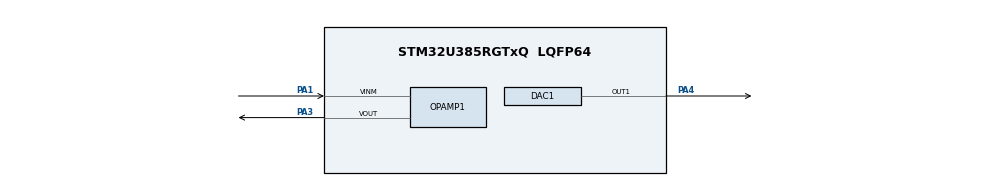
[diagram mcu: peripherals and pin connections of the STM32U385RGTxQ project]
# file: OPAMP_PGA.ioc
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CORTEX_M33_NS.userName=CORTEX_M33
DAC1.DAC_AutonomousMode=DAC_AUTONOMOUS_MODE_DISABLE
DAC1.DAC_Channel-DAC_OUT1_ExtAndInt=DAC_CHANNEL_1
DAC1.DAC_Channel-DAC_OUT2_ExtAndInt=DAC_CHANNEL_1
DAC1.DAC_Trigger-DAC_OUT1_ExtAndInt=DAC_TRIGGER_T2_TRGO
DAC1.DAC_Trigger-DAC_OUT2_ExtAndInt=DAC_TRIGGER_T2_TRGO
GPDMA1.CIRCULARMODE_GPDMACH1=ENABLE
GPDMA1.DESTDATAWIDTH_GPDMACH1=DMA_DEST_DATAWIDTH_WORD
GPDMA1.DIRECTION_GPDMACH1=DMA_MEMORY_TO_PERIPH
GPDMA1.IPHANDLE_GPDMACH1-SIMPLEREQUEST_GPDMACH1=__NULL
GPDMA1.LINKALLOCATEDPORT_CIRCULAR_GPDMACH1=DMA_LINK_ALLOCATED_PORT0
GPDMA1.REQUEST_GPDMACH1=GPDMA1_REQUEST_DAC1_CH1
GPDMA1.SRCDATAWIDTH_GPDMACH1=DMA_SRC_DATAWIDTH_HALFWORD
GPDMA1.SRCINC_GPDMACH1=DMA_SINC_INCREMENTED
GPDMA1.TRANSFERALLOCATEDPORTSRC_GPDMACH1=DMA_SRC_ALLOCATED_PORT1
Mcu.Family=STM32U3
Mcu.Name=STM32U385RGTxQ
Mcu.Package=LQFP64
NVIC.GPDMA1_Channel1_IRQn=true\:0\:0\:false\:false\:true\:false\:true\:true
NVIC.PriorityGroup=NVIC_PRIORITYGROUP_4
PA1.Mode=PGA Connected-DAC_OUT1-INP
PA1.PinAttribute=CortexM33
PA1.Signal=OPAMP1_VINM
PA3.Mode=PGA Connected-DAC_OUT1-INP
PA3.PinAttribute=CortexM33
PA3.Signal=OPAMP1_VOUT
PA4.PinAttribute=CortexM33
PA4.Signal=COMP_DAC11_group
ProjectManager.HeapSize=0x200
ProjectManager.StackSize=0x400
ProjectManager.TargetToolchain=EWARM V9.20
RCC.ADCFreq_Value=96000000
RCC.AHBFreq_Value=96000000
RCC.APB1Freq_Value=96000000
RCC.APB1TimFreq_Value=96000000
RCC.APB2Freq_Value=96000000
RCC.APB2TimFreq_Value=96000000
RCC.APB3Freq_Value=96000000
RCC.CortexFreq_Value=12000000
RCC.HCLKFreq_Value=96000000
RCC.HSE_VALUE=16000000
RCC.HSI48_VALUE=48000000
RCC.HSI_VALUE=16000000
RCC.LSE_VALUE=32768
RCC.LSIDIV_VALUE=32000
RCC.MSISDIV=RCC_MSI_DIV1
RCC.MSI_VALUE=96000000
RCC.PWR_Regulator_Voltage_Scale=PWR_REGULATOR_VOLTAGE_SCALE1
RCC.SYSCLKFreq_VALUE=96000000
RCC.USBFreq_Value=96000000
SH.COMP_DAC11_group.0=DAC1_OUT1,DAC_OUT1_ExtAndInt
TIM2.AutoReloadPreload=TIM_AUTORELOAD_PRELOAD_DISABLE
TIM2.ClockDivision=TIM_CLOCKDIVISION_DIV1
TIM2.CounterMode=TIM_COUNTERMODE_UP
TIM2.Dithering=Disable
TIM2.Period=0xFFFF
TIM2.PeriodNoDither=0xFFFF
TIM2.Prescaler=0
TIM2.TIM_MasterOutputTrigger=TIM_TRGO_UPDATE
TIM2.TIM_MasterSlaveMode=TIM_MASTERSLAVEMODE_DISABLE
VP_GPDMA1_VS_GPDMACH1.Mode=SIMPLEREQUEST_GPDMACH1
VP_ICACHE_VS_ICACHE.Mode=DirectMappedCache
VP_PWR_VS_DBSignals.Mode=DisableDeadBatterySignals
VP_PWR_VS_LPOM.Mode=PowerOptimisation
VP_PWR_VS_SECSignals.Mode=Security/Privilege
VP_TIM2_VS_ClockSourceINT.Mode=Internal
board=custom

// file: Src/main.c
/* USER CODE BEGIN Header */
/**
  ******************************************************************************
  * @file           : main.c
  * @brief          : Main program body
  ******************************************************************************
  * @attention
  *
  * Copyright (c) 2024 STMicroelectronics.
  * All rights reserved.
  *
  * This software is licensed under terms that can be found in the LICENSE file
  * in the root directory of this software component.
  * If no LICENSE file comes with this software, it is provided AS-IS.
  *
  ******************************************************************************
  */
/* USER CODE END Header */
#include "main.h"

/* USER CODE BEGIN Includes */
#include "stm32u3xx_nucleo.h"
/* USER CODE END Includes */

DAC_HandleTypeDef hdac1;
DMA_NodeTypeDef Node_GPDMA1_Channel1;
DMA_QListTypeDef List_GPDMA1_Channel1;
DMA_HandleTypeDef handle_GPDMA1_Channel1;

OPAMP_HandleTypeDef hopamp1;

TIM_HandleTypeDef htim2;

/* USER CODE BEGIN PV */
/* Private variables ---------------------------------------------------------*/
/* set to 1 after User push-button interrupt  */
__IO uint32_t UserButtonStatus = 0;

const uint16_t Sine12bit[32] = { 511,  611,  707,  796,  873,  937,  984, 1013,
                                1023, 1013,  984,  937,  873,  796,  707,  611,
                                 511,  412,  315,  227,  149,   86,   38,    9,
                                   0,    9,   38,   86,  149,  227,  315,  412};
/* USER CODE END PV */

void SystemClock_Config(void);
static void MX_GPIO_Init(void);
static void MX_GPDMA1_Init(void);
static void MX_DAC1_Init(void);
static void MX_ICACHE_Init(void);
static void MX_TIM2_Init(void);
static void MX_OPAMP1_Init(void);
/* USER CODE BEGIN PFP */
/* Private function prototypes -----------------------------------------------*/
void OPAMP_Config_lowPower(void);
void DAC_Config_lowPower(void);
/* USER CODE END PFP */

int main(void)
{

  /* MCU Configuration--------------------------------------------------------*/

  /* Reset of all peripherals, Initializes the Flash interface and the Systick. */
  HAL_Init();

  /* Configure the system clock */
  SystemClock_Config();

  /* Initialize all configured peripherals */
  MX_GPIO_Init();
  MX_GPDMA1_Init();
  MX_DAC1_Init();
  MX_ICACHE_Init();
  MX_TIM2_Init();
  MX_OPAMP1_Init();
  /* USER CODE BEGIN 2 */
  /* Initialize the User push-button.
     It is used for changing the gain */
  BSP_PB_Init(BUTTON_USER, BUTTON_MODE_EXTI);
  /* USER CODE END 2 */

  /* Infinite loop */
  /* USER CODE BEGIN WHILE */
  /*##- Enable DAC Channel and associated DMA ##############################*/
  if(HAL_OK != HAL_DAC_Start_DMA(&hdac1, DAC_CHANNEL_1,
                       (uint32_t*)Sine12bit, 32, DAC_ALIGN_12B_R))
  {
    /* Start DMA Error */
    Error_Handler();
  }
  /*##- Enable TIM peripheral counter ######################################*/
  if(HAL_OK != HAL_TIM_Base_Start(&htim2))
  {
    Error_Handler();
  }
  /*##- Start OPAMP    #####################################################*/
  /* Enable OPAMP */
  if(HAL_OK != HAL_OPAMP_Start(&hopamp1))
  {
    Error_Handler();
  }

  while (1)
  {
    /* Test if user an action occurred on the User push-button */
    if (UserButtonStatus == 1)
    {
      HAL_Delay(200);
      UserButtonStatus = 0;
      /* Change the gain */
      if (hopamp1.Init.PgaGain == OPAMP_PGA_GAIN_4)
      {
        hopamp1.Init.PgaGain = OPAMP_PGA_GAIN_2;
      }
      else
      {
        hopamp1.Init.PgaGain = OPAMP_PGA_GAIN_4;
      }
      /* Update OPAMP config */
      /* Gain is changed on the fly */
      if(HAL_OK != HAL_OPAMP_Init(&hopamp1))
      {
        Error_Handler();
      }
    }
  }
    /* USER CODE END WHILE */

}

void SystemClock_Config(void)
{
  RCC_OscInitTypeDef RCC_OscInitStruct = {0};
  RCC_ClkInitTypeDef RCC_ClkInitStruct = {0};

  /** Enable Epod Booster
  */
  if (HAL_RCCEx_EpodBoosterClkConfig(RCC_EPODBOOSTER_SOURCE_MSIS, RCC_EPODBOOSTER_DIV1) != HAL_OK)
  {
    Error_Handler();
  }
  if (HAL_PWREx_EnableEpodBooster() != HAL_OK)
  {
    Error_Handler();
  }

  /** Configure the main internal regulator output voltage
  */
  if (HAL_PWREx_ControlVoltageScaling(PWR_REGULATOR_VOLTAGE_SCALE1) != HAL_OK)
  {
    Error_Handler();
  }

  /** Set Flash latency before increasing MSIS
  */
  __HAL_FLASH_SET_LATENCY(FLASH_LATENCY_2);

  /** Initializes the CPU, AHB and APB buses clocks
  */
  RCC_OscInitStruct.OscillatorType = RCC_OSCILLATORTYPE_LSI|RCC_OSCILLATORTYPE_MSIS;
  RCC_OscInitStruct.LSIState = RCC_LSI_ON;
  RCC_OscInitStruct.LSIDiv = RCC_LSI_DIV1;
  RCC_OscInitStruct.MSISState = RCC_MSI_ON;
  RCC_OscInitStruct.MSISSource = RCC_MSI_RC0;
  RCC_OscInitStruct.MSISDiv = RCC_MSI_DIV1;
  if (HAL_RCC_OscConfig(&RCC_OscInitStruct) != HAL_OK)
  {
    Error_Handler();
  }

  /** Initializes the CPU, AHB and APB buses clocks
  */
  RCC_ClkInitStruct.ClockType = RCC_CLOCKTYPE_HCLK|RCC_CLOCKTYPE_SYSCLK
                              |RCC_CLOCKTYPE_PCLK1|RCC_CLOCKTYPE_PCLK2
                              |RCC_CLOCKTYPE_PCLK3;
  RCC_ClkInitStruct.SYSCLKSource = RCC_SYSCLKSOURCE_MSIS;
  RCC_ClkInitStruct.AHBCLKDivider = RCC_SYSCLK_DIV1;
  RCC_ClkInitStruct.APB1CLKDivider = RCC_HCLK_DIV1;
  RCC_ClkInitStruct.APB2CLKDivider = RCC_HCLK_DIV1;
  RCC_ClkInitStruct.APB3CLKDivider = RCC_HCLK_DIV1;

  if (HAL_RCC_ClockConfig(&RCC_ClkInitStruct, FLASH_LATENCY_2) != HAL_OK)
  {
    Error_Handler();
  }
}

static void MX_DAC1_Init(void)
{

  DAC_ChannelConfTypeDef sConfig = {0};
  DAC_AutonomousModeConfTypeDef sAutonomousMode = {0};

  /** DAC Initialization
  */
  hdac1.Instance = DAC1;
  if (HAL_DAC_Init(&hdac1) != HAL_OK)
  {
    Error_Handler();
  }

  /** DAC channel OUT1 config
  */
  sConfig.DAC_HighFrequency = DAC_HIGH_FREQUENCY_INTERFACE_MODE_DISABLE;
  sConfig.DAC_DMADoubleDataMode = DISABLE;
  sConfig.DAC_SignedFormat = DISABLE;
  sConfig.DAC_SampleAndHold = DAC_SAMPLEANDHOLD_DISABLE;
  sConfig.DAC_Trigger = DAC_TRIGGER_T2_TRGO;
  sConfig.DAC_OutputBuffer = DAC_OUTPUTBUFFER_ENABLE;
  sConfig.DAC_ConnectOnChipPeripheral = DAC_CHIPCONNECT_BOTH;
  sConfig.DAC_UserTrimming = DAC_TRIMMING_FACTORY;
  if (HAL_DAC_ConfigChannel(&hdac1, &sConfig, DAC_CHANNEL_1) != HAL_OK)
  {
    Error_Handler();
  }

  /** Configure Autonomous Mode
  */
  sAutonomousMode.AutonomousModeState = DAC_AUTONOMOUS_MODE_DISABLE;
  if (HAL_DACEx_SetConfigAutonomousMode(&hdac1, &sAutonomousMode) != HAL_OK)
  {
    Error_Handler();
  }

}

static void MX_GPDMA1_Init(void)
{

  /* Peripheral clock enable */
  __HAL_RCC_GPDMA1_CLK_ENABLE();

  /* GPDMA1 interrupt Init */
    HAL_NVIC_SetPriority(GPDMA1_Channel1_IRQn, 0, 0);
    HAL_NVIC_EnableIRQ(GPDMA1_Channel1_IRQn);

}

static void MX_ICACHE_Init(void)
{

  /** Enable instruction cache in 1-way (direct mapped cache)
  */
  if (HAL_ICACHE_ConfigAssociativityMode(ICACHE_1WAY) != HAL_OK)
  {
    Error_Handler();
  }
  if (HAL_ICACHE_Enable() != HAL_OK)
  {
    Error_Handler();
  }

}

static void MX_OPAMP1_Init(void)
{

  hopamp1.Instance = OPAMP1;
  hopamp1.Init.Mode = OPAMP_PGA_MODE;
  hopamp1.Init.NonInvertingInput = OPAMP_NONINVERTINGINPUT_DAC_CH;
  hopamp1.Init.InvertingInput = OPAMP_INVERTINGINPUT_IO0;
  hopamp1.Init.PowerMode = OPAMP_POWERMODE_NORMALPOWER_NORMALSPEED;
  hopamp1.Init.PgaGain = OPAMP_PGA_GAIN_2;
  hopamp1.Init.UserTrimming = OPAMP_TRIMMING_FACTORY;
  if (HAL_OPAMP_Init(&hopamp1) != HAL_OK)
  {
    Error_Handler();
  }

}

static void MX_TIM2_Init(void)
{

  TIM_ClockConfigTypeDef sClockSourceConfig = {0};
  TIM_MasterConfigTypeDef sMasterConfig = {0};

  htim2.Instance = TIM2;
  htim2.Init.Prescaler = 0;
  htim2.Init.CounterMode = TIM_COUNTERMODE_UP;
  htim2.Init.Period = 0xFFFF;
  htim2.Init.ClockDivision = TIM_CLOCKDIVISION_DIV1;
  htim2.Init.AutoReloadPreload = TIM_AUTORELOAD_PRELOAD_DISABLE;
  if (HAL_TIM_Base_Init(&htim2) != HAL_OK)
  {
    Error_Handler();
  }
  sClockSourceConfig.ClockSource = TIM_CLOCKSOURCE_INTERNAL;
  if (HAL_TIM_ConfigClockSource(&htim2, &sClockSourceConfig) != HAL_OK)
  {
    Error_Handler();
  }
  sMasterConfig.MasterOutputTrigger = TIM_TRGO_UPDATE;
  sMasterConfig.MasterSlaveMode = TIM_MASTERSLAVEMODE_DISABLE;
  if (HAL_TIMEx_MasterConfigSynchronization(&htim2, &sMasterConfig) != HAL_OK)
  {
    Error_Handler();
  }

}

static void MX_GPIO_Init(void)
{

  /* GPIO Ports Clock Enable */
  __HAL_RCC_GPIOA_CLK_ENABLE();

}

/* USER CODE BEGIN 4 */

/**
  * @brief  EXTI line detection callbacks.
  * @param  GPIO_Pin: Specifies the pins connected EXTI line
  * @retval None
  */
void HAL_GPIO_EXTI_Rising_Callback(uint16_t GPIO_Pin)
{
  if (GPIO_Pin == BUTTON_USER_PIN)
  {
    UserButtonStatus = 1;
  }
}
/* USER CODE END 4 */

void Error_Handler(void)
{
  __disable_irq();
  while (1)
  {
  }
}

#ifdef  USE_FULL_ASSERT
/**
  * @brief  Reports the name of the source file and the source line number
  *         where the assert_param error has occurred.
  * @param  file: pointer to the source file name
  * @param  line: assert_param error line source number
  * @retval None
  */
void assert_failed(uint8_t *file, uint32_t line)
{
  /* USER CODE BEGIN 6 */
  /* User can add his own implementation to report the file name and line number,
    ex: printf("Wrong parameters value: file %s on line %d\r\n", file, line) */
  Error_Handler();
  /* USER CODE END 6 */
}
#endif /* USE_FULL_ASSERT */
